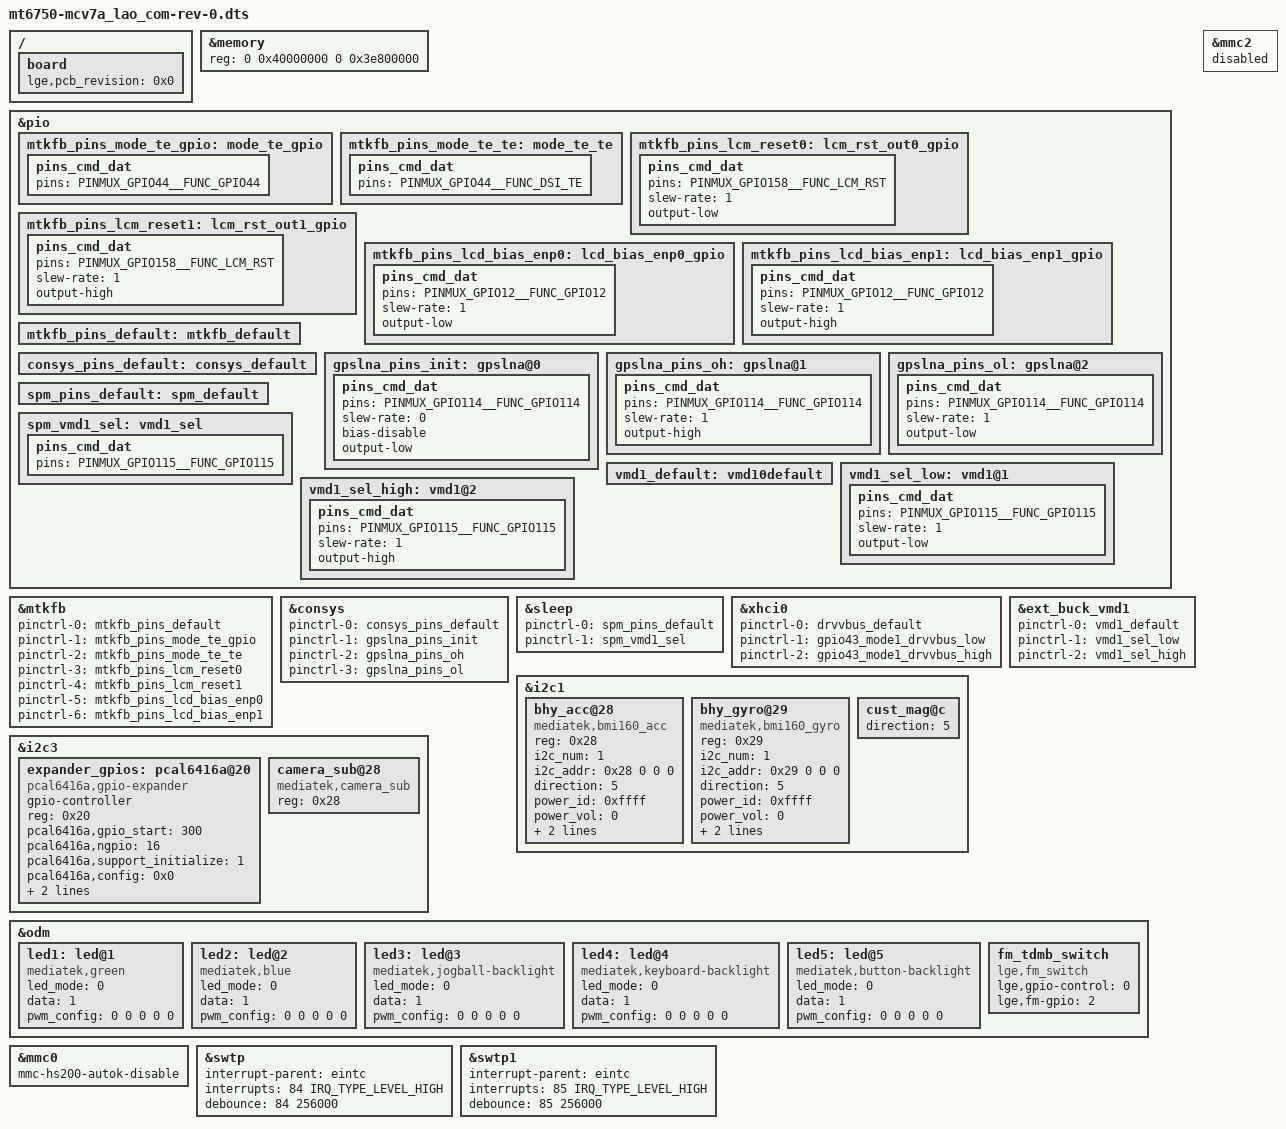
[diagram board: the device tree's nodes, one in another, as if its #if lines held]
#include <generated/autoconf.h>
/dts-v1/;

#ifdef CONFIG_MTK_DTBO_FEATURE
/plugin/;
#include <dt-bindings/mmc/mt6755-msdc.h>
#include "../../mt6755-pinfunc.h"
#else
#include "../../mt6755.dts"
#endif

#include "mt6750-mcv7a_lao_com-cust.dtsi"
#include "mt6750-mcv7a_lao_com-power.dtsi"
#include "mt6750-mcv7a_lao_com-power-slave_charger.dtsi"
#include "mt6750-mcv7a_lao_com-panel.dtsi"
#include "mt6750-mcv7a_lao_com-touch.dtsi"
#include "mt6750-mcv7a_lao_com-sensor.dtsi"
#include "mt6750-mcv7a_lao_com-fingerprint.dtsi"
#include "mt6750-mcv7a_lao_com-misc.dtsi"
#include "mt6750-mcv7a_lao_com-sound-rev-0.dtsi"
//#include "mt6750-mcv7a_lao_com-nfc-rev-0.dtsi"
#include "mt6750-mcv7a_lao_com-common.dtsi"
#include "mt6750-mcv7a_lao_com-usb.dtsi"
#include "mt6750-mcv7a_lao_com-camera-rev-0.dtsi"

/ {
	board {
		/*
		   typedef enum {
		   HW_REV_0 = 0,
		   HW_REV_0_1,
		   HW_REV_A,
		   HW_REV_B,
		   HW_REV_C,
		   HW_REV_1_0,
		   HW_REV_1_1,
		   HW_REV_MAX
		   } rev_type;
		 */
		lge,pcb_revision = <0x0>; // rev_0
	};
};

&memory {
	device_type = "memory";
	reg = <0 0x40000000 0 0x3e800000>;
};

/* DISPSYS GPIO standardization */
&pio {

	mtkfb_pins_mode_te_gpio: mode_te_gpio {
		pins_cmd_dat {
			pins = <PINMUX_GPIO44__FUNC_GPIO44>;
		};
	};

	mtkfb_pins_mode_te_te: mode_te_te {
		pins_cmd_dat {
			pins = <PINMUX_GPIO44__FUNC_DSI_TE>;
		};
	};

	mtkfb_pins_lcm_reset0: lcm_rst_out0_gpio {
		pins_cmd_dat {
			pins = <PINMUX_GPIO158__FUNC_LCM_RST>;
			slew-rate = <1>;
			output-low;
		};
	};

	mtkfb_pins_lcm_reset1: lcm_rst_out1_gpio {
		pins_cmd_dat {
			pins = <PINMUX_GPIO158__FUNC_LCM_RST>;
			slew-rate = <1>;
			output-high;
		};
	};

	mtkfb_pins_lcd_bias_enp0: lcd_bias_enp0_gpio {
		pins_cmd_dat {
			pins = <PINMUX_GPIO12__FUNC_GPIO12>;
			slew-rate = <1>;
			output-low;
		};
	};

	mtkfb_pins_lcd_bias_enp1: lcd_bias_enp1_gpio {
		pins_cmd_dat {
			pins = <PINMUX_GPIO12__FUNC_GPIO12>;
			slew-rate = <1>;
			output-high;
		};
	};

	mtkfb_pins_default: mtkfb_default {
	};
};

&mtkfb {
	pinctrl-names = "default", "mode_te_gpio", "mode_te_te", "lcm_rst_out0_gpio",
	"lcm_rst_out1_gpio", "lcd_bias_enp0_gpio", "lcd_bias_enp1_gpio";
	pinctrl-0 = <&mtkfb_pins_default>;
	pinctrl-1 = <&mtkfb_pins_mode_te_gpio>;
	pinctrl-2 = <&mtkfb_pins_mode_te_te>;
	pinctrl-3 = <&mtkfb_pins_lcm_reset0>;
	pinctrl-4 = <&mtkfb_pins_lcm_reset1>;
	pinctrl-5 = <&mtkfb_pins_lcd_bias_enp0>;
	pinctrl-6 = <&mtkfb_pins_lcd_bias_enp1>;
	status = "okay";
};/* DISPSYS GPIO standardization end */

/* CONSYS GPIO standardization */
&pio {
	consys_pins_default: consys_default {
	};

	gpslna_pins_init: gpslna@0 {
		pins_cmd_dat {
			pins = <PINMUX_GPIO114__FUNC_GPIO114>;
			slew-rate = <0>;
			bias-disable;
			output-low;
		};
	};

	gpslna_pins_oh: gpslna@1 {
		pins_cmd_dat {
			pins = <PINMUX_GPIO114__FUNC_GPIO114>;
			slew-rate = <1>;
			output-high;
		};
	};

	gpslna_pins_ol: gpslna@2 {
		pins_cmd_dat {
			pins = <PINMUX_GPIO114__FUNC_GPIO114>;
			slew-rate = <1>;
			output-low;
		};
	};
};

&consys {
	pinctrl-names = "default", "gps_lna_state_init", "gps_lna_state_oh", "gps_lna_state_ol";
	pinctrl-0 = <&consys_pins_default>;
	pinctrl-1 = <&gpslna_pins_init>;
	pinctrl-2 = <&gpslna_pins_oh>;
	pinctrl-3 = <&gpslna_pins_ol>;
	status = "okay";
};
/* CONSYS end */

/* SPM GPIO standardization */
&pio {
	spm_pins_default: spm_default {
	};

	spm_vmd1_sel: vmd1_sel {
		pins_cmd_dat {
			pins = <PINMUX_GPIO115__FUNC_GPIO115>;
		};
	};

};

&sleep {
	pinctrl-names = "default", "vmd1_sel";
	pinctrl-0 = <&spm_pins_default>;
	pinctrl-1 = <&spm_vmd1_sel>;
	status = "okay";
};
/* SPM end */

&xhci0 {
	pinctrl-names = "drvvbus_default", "drvvbus_low", "drvvbus_high";
	pinctrl-0 = <&drvvbus_default>;
	pinctrl-1 = <&gpio43_mode1_drvvbus_low>;
	pinctrl-2 = <&gpio43_mode1_drvvbus_high>;
	status = "okay";
};

&i2c1 {
	/* sensor start */
	bhy_acc@28{
	    compatible = "mediatek,bmi160_acc";
	    reg = <0x28>;
	    status = "okay";
	    i2c_num = <1>;
	    i2c_addr = <0x28 0 0 0>;
	    direction = <5>;
	    power_id = <0xffff>;
	    power_vol = <0>;
	    firlen = <0>;
	    is_batch_supported = <0>;
	};
	bhy_gyro@29{
	    compatible = "mediatek,bmi160_gyro";
	    reg = <0x29>;
	    status = "okay";
	    i2c_num = <1>;
	    i2c_addr = <0x29 0 0 0>;
	    direction = <5>;
	    power_id = <0xffff>;
	    power_vol = <0>;
	    firlen = <0>;
	    is_batch_supported = <0>;
	};
	cust_mag@c {
		direction = <5>;
	};
};

&i2c3 {
	/* CONFIG_GPIO_PCAL6416A, rev.a */
	expander_gpios: pcal6416a@20 {
		compatible = "pcal6416a,gpio-expander";
		gpio-controller;
		#gpio-cells = <2>;
		reg = <0x20>;
		pcal6416a,gpio_start = <300>;
		pcal6416a,ngpio = <16>;
		pcal6416a,support_initialize = <1>;
		/* config, 15 ~ 0, 1bit configure[1:input, 0:output] */
		pcal6416a,config = <0x0>;    /* 0000 0000 0000 0000 */
		/* data_out, 15 ~ 0, 1bit configure[1:high, 0:low]*/
		pcal6416a,data_out = <0x0>;  /* 0000 0000 0000 0000 */
		/* pull_reg, 31 ~ 0, 2bit configure[00:no_pull, 01:pull_down, 10:pull_up, 11:not used]*/
		pcal6416a,pull_reg = <0x55555555>; /* 01 01 01 01 / 01 01 01 01 /  01 01 01 01 / 01 01 01 01 */
	};

	camera_sub@28 {
		compatible = "mediatek,camera_sub";
		reg = <0x28>;
		status = "okay";
	};
};

&ext_buck_vmd1 {
	pinctrl-names = "default", "vmd1_sel_low", "vmd1_sel_high";

	pinctrl-0 = <&vmd1_default>;
	pinctrl-1 = <&vmd1_sel_low>;
	pinctrl-2 = <&vmd1_sel_high>;
};

&pio {
	vmd1_default: vmd10default {
	};

	vmd1_sel_low: vmd1@1 {
		pins_cmd_dat {
			pins = <PINMUX_GPIO115__FUNC_GPIO115>;
			slew-rate = <1>;
			output-low;
		};
	};

	vmd1_sel_high: vmd1@2 {
		pins_cmd_dat {
			pins = <PINMUX_GPIO115__FUNC_GPIO115>;
			slew-rate = <1>;
			output-high;
		};
	};
};

&odm {
	led1:led@1 {
		compatible = "mediatek,green";
		led_mode = <0>;
		data = <1>;
		pwm_config = <0 0 0 0 0>;
	};
	led2:led@2 {
		compatible = "mediatek,blue";
		led_mode = <0>;
		data = <1>;
		pwm_config = <0 0 0 0 0>;
	};
	led3:led@3 {
		compatible = "mediatek,jogball-backlight";
		led_mode = <0>;
		data = <1>;
		pwm_config = <0 0 0 0 0>;
	};
	led4:led@4 {
		compatible = "mediatek,keyboard-backlight";
		led_mode = <0>;
		data = <1>;
		pwm_config = <0 0 0 0 0>;
	};
	led5:led@5 {
		compatible = "mediatek,button-backlight";
		led_mode = <0>;
		data = <1>;
		pwm_config = <0 0 0 0 0>;
	};

	fm_tdmb_switch {
		compatible = "lge,fm_switch";
		status = "okay";
		lge,gpio-control = <0>;
		lge,fm-gpio = <2>;
	};
};

&mmc2 {
	status = "disable";
};

&mmc0 {
	mmc-hs200-autok-disable;
};

/* SWTP GPIO standardization - byeongha.kim@lge.com */
&swtp {
    interrupt-parent = <&eintc>;
    interrupts = <84 IRQ_TYPE_LEVEL_HIGH>;
    debounce = <84 256000>;
    status = "okay";
    };

&swtp1 {
    interrupt-parent = <&eintc>;
    interrupts = <85 IRQ_TYPE_LEVEL_HIGH>;
    debounce = <85 256000>;
    status = "okay";
    };
/* SWTP end */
